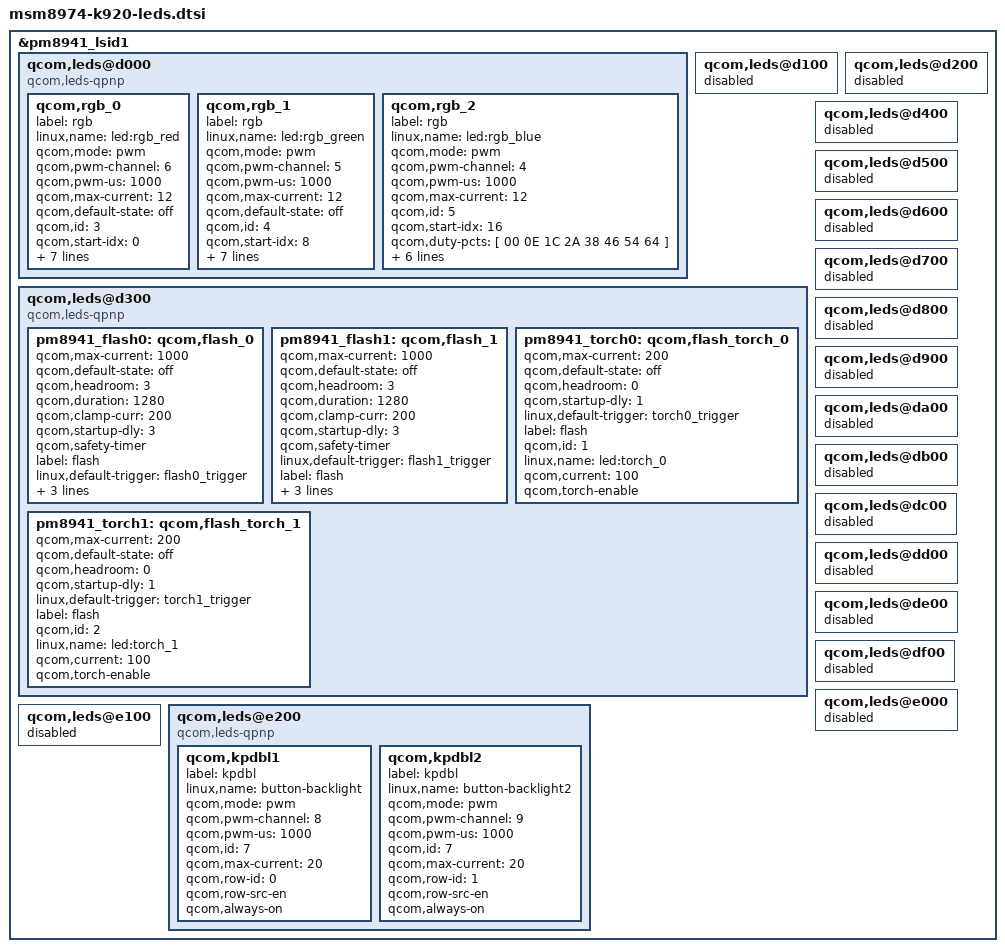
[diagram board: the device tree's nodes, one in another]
/*
 * Copyright (c) 2012-2013, The Linux Foundation. All rights reserved.
 *
 * This program is free software; you can redistribute it and/or modify
 * it under the terms of the GNU General Public License version 2 and
 * only version 2 as published by the Free Software Foundation.
 *
 * This program is distributed in the hope that it will be useful,
 * but WITHOUT ANY WARRANTY; without even the implied warranty of
 * MERCHANTABILITY or FITNESS FOR A PARTICULAR PURPOSE.  See the
 * GNU General Public License for more details.
 */

&pm8941_lsid1 {
	qcom,leds@d000 {
		compatible = "qcom,leds-qpnp";
		status = "okay";
		qcom,rgb_0 {
			label = "rgb";
			linux,name = "led:rgb_red";
			qcom,mode = "pwm";
			qcom,pwm-channel = <6>;
			qcom,pwm-us = <1000>;
			qcom,max-current = <12>;
			qcom,default-state = "off";
			qcom,id = <3>;
			qcom,start-idx = <0>;
			qcom,duty-pcts = [ 00 0E 1C 2A 38 46 54 64 ];
			qcom,pause-lo = <500>;
			qcom,pause-hi = <500>;
			qcom,ramp-step-ms = <50>;
			qcom,lut-flags = <31>; /*  loop, ramp up, reverse, pause hi, pause lo */
			linux,default-trigger = "none";
			qcom,use-blink;
		};

		qcom,rgb_1 {
			label = "rgb";
			linux,name = "led:rgb_green";
			qcom,mode = "pwm";
			qcom,pwm-channel = <5>;
			qcom,pwm-us = <1000>;
			qcom,max-current = <12>;
			qcom,default-state = "off";
			qcom,id = <4>;
			qcom,start-idx = <8>;
			qcom,duty-pcts = [ 00 0E 1C 2A 38 46 54 64 ];
			qcom,pause-lo = <500>;
			qcom,pause-hi = <500>;
			qcom,ramp-step-ms = <50>;
			qcom,lut-flags = <31>; /*  loop, ramp up, reverse, pause hi, pause lo */
			linux,default-trigger = "none";
			qcom,use-blink;
		};

		qcom,rgb_2 {
			label = "rgb";
			linux,name = "led:rgb_blue";
			qcom,mode = "pwm";
			qcom,pwm-channel = <4>;
			qcom,pwm-us = <1000>;
			qcom,max-current = <12>;
			qcom,id = <5>;
			qcom,start-idx = <16>;
			qcom,duty-pcts = [ 00 0E 1C 2A 38 46 54 64 ];
			qcom,pause-lo = <500>;
			qcom,pause-hi = <500>;
			qcom,ramp-step-ms = <50>;
			qcom,lut-flags = <31>; /*  loop, ramp up, reverse, pause hi, pause lo */
			linux,default-trigger = "none";
			qcom,use-blink;
		};
	};

	qcom,leds@d100 {
		status = "disabled";
	};

	qcom,leds@d200 {
		status = "disabled";
	};

	qcom,leds@d300 {
		compatible = "qcom,leds-qpnp";
		status = "okay";

		/* Flash */
		pm8941_flash0: qcom,flash_0 {
			qcom,max-current = <1000>;
			qcom,default-state = "off";
			qcom,headroom = <3>;
			qcom,duration = <1280>;
			qcom,clamp-curr = <200>;
			qcom,startup-dly = <3>;
			qcom,safety-timer;
			label = "flash";
			linux,default-trigger =
				"flash0_trigger";
			qcom,id = <1>;
			linux,name = "led:flash_0";
			qcom,current = <625>;
		};

		pm8941_flash1: qcom,flash_1 {
			qcom,max-current = <1000>;
			qcom,default-state = "off";
			qcom,headroom = <3>;
			qcom,duration = <1280>;
			qcom,clamp-curr = <200>;
			qcom,startup-dly = <3>;
			qcom,safety-timer;
			linux,default-trigger =
				"flash1_trigger";
			label = "flash";
			qcom,id = <2>;
			linux,name = "led:flash_1";
			qcom,current = <625>;
		};

		/* Torch */
		pm8941_torch0: qcom,flash_torch_0 {
			qcom,max-current = <200>;
			qcom,default-state = "off";
			qcom,headroom = <0>;
			qcom,startup-dly = <1>;
			linux,default-trigger =
				"torch0_trigger";
			label = "flash";
			qcom,id = <1>;
			linux,name = "led:torch_0";
			qcom,current = <100>;
			qcom,torch-enable;
		};

		pm8941_torch1: qcom,flash_torch_1 {
			qcom,max-current = <200>;
			qcom,default-state = "off";
			qcom,headroom = <0>;
			qcom,startup-dly = <1>;
			linux,default-trigger =
				"torch1_trigger";
			label = "flash";
			qcom,id = <2>;
			linux,name = "led:torch_1";
			qcom,current = <100>;
			qcom,torch-enable;
		};
	};

	qcom,leds@d400 {
		status = "disabled";
	};

	qcom,leds@d500 {
		status = "disabled";
	};

	qcom,leds@d600 {
		status = "disabled";
	};

	qcom,leds@d700 {
		status = "disabled";
	};

	qcom,leds@d800 {
		status = "disabled";
	};

	qcom,leds@d900 {
		status = "disabled";
	};

	qcom,leds@da00 {
		status = "disabled";
	};

	qcom,leds@db00 {
		status = "disabled";
	};

	qcom,leds@dc00 {
		status = "disabled";
	};

	qcom,leds@dd00 {
		status = "disabled";
	};

	qcom,leds@de00 {
		status = "disabled";
	};

	qcom,leds@df00 {
		status = "disabled";
	};

	qcom,leds@e000 {
		status = "disabled";
	};

	qcom,leds@e100 {
		status = "disabled";
	};

	qcom,leds@e200 {
		compatible = "qcom,leds-qpnp";

		qcom,kpdbl1 {
			label = "kpdbl";
			linux,name = "button-backlight";
			qcom,mode = "pwm";
			qcom,pwm-channel = <8>;
			qcom,pwm-us = <1000>;
			qcom,id = <7>;
			qcom,max-current = <20>;
			qcom,row-id = <0>;
			qcom,row-src-en;
			qcom,always-on;
		};

		qcom,kpdbl2 {
			label = "kpdbl";
			linux,name = "button-backlight2";
			qcom,mode = "pwm";
			qcom,pwm-channel = <9>;
			qcom,pwm-us = <1000>;
			qcom,id = <7>;
			qcom,max-current = <20>;
			qcom,row-id = <1>;
			qcom,row-src-en;
			qcom,always-on;
		};
	};
};
